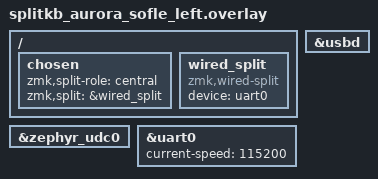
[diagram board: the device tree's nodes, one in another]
/ {
    chosen {
        /* Ta połowa jest centralna (lewa, z USB) */
        zmk,split-role = "central";
        zmk,split = &wired_split;
    };

    wired_split: wired_split {
        compatible = "zmk,wired-split";
        device = <&uart0>;
    };
};

&usbd {
    status = "okay";
};

&zephyr_udc0 {
    status = "okay";
};

&uart0 {
    status = "okay";
    current-speed = <115200>;
};
